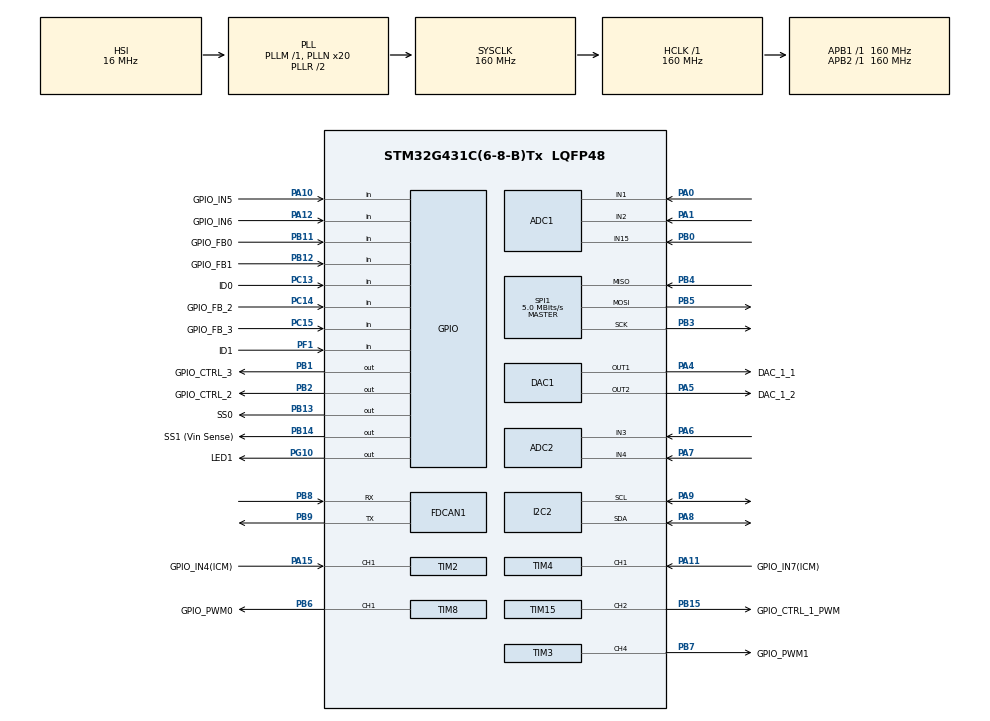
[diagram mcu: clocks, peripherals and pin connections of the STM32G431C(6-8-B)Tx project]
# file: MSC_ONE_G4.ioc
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ADC1.Channel-1\#ChannelRegularConversion=ADC_CHANNEL_1
ADC1.Channel-2\#ChannelRegularConversion=ADC_CHANNEL_2
ADC1.Channel-3\#ChannelRegularConversion=ADC_CHANNEL_15
ADC1.ClockPrescaler=ADC_CLOCK_ASYNC_DIV32
ADC1.ContinuousConvMode=ENABLE
ADC1.DMAContinuousRequests=ENABLE
ADC1.EOCSelection=ADC_EOC_SEQ_CONV
ADC1.NbrOfConversion=3
ADC1.NbrOfConversionFlag=1
ADC1.OffsetNumber-1\#ChannelRegularConversion=ADC_OFFSET_NONE
ADC1.OffsetNumber-2\#ChannelRegularConversion=ADC_OFFSET_NONE
ADC1.OffsetNumber-3\#ChannelRegularConversion=ADC_OFFSET_NONE
ADC1.Rank-1\#ChannelRegularConversion=1
ADC1.Rank-2\#ChannelRegularConversion=2
ADC1.Rank-3\#ChannelRegularConversion=3
ADC1.SamplingTime-1\#ChannelRegularConversion=ADC_SAMPLETIME_92CYCLES_5
ADC1.SamplingTime-2\#ChannelRegularConversion=ADC_SAMPLETIME_92CYCLES_5
ADC1.SamplingTime-3\#ChannelRegularConversion=ADC_SAMPLETIME_92CYCLES_5
ADC1.master=1
ADC2.Channel-0\#ChannelRegularConversion=ADC_CHANNEL_3
ADC2.Channel-1\#ChannelRegularConversion=ADC_CHANNEL_4
ADC2.ClockPrescaler=ADC_CLOCK_ASYNC_DIV32
ADC2.ContinuousConvMode=ENABLE
ADC2.DMAContinuousRequests=ENABLE
ADC2.EOCSelection=ADC_EOC_SEQ_CONV
ADC2.NbrOfConversion=2
ADC2.NbrOfConversionFlag=1
ADC2.OffsetNumber-0\#ChannelRegularConversion=ADC_OFFSET_NONE
ADC2.OffsetNumber-1\#ChannelRegularConversion=ADC_OFFSET_NONE
ADC2.Rank-0\#ChannelRegularConversion=1
ADC2.Rank-1\#ChannelRegularConversion=2
ADC2.SamplingTime-0\#ChannelRegularConversion=ADC_SAMPLETIME_92CYCLES_5
ADC2.SamplingTime-1\#ChannelRegularConversion=ADC_SAMPLETIME_92CYCLES_5
DAC1.DAC_Channel-DAC_OUT2=DAC_CHANNEL_2
Dma.ADC1.1.Direction=DMA_PERIPH_TO_MEMORY
Dma.ADC1.1.EventEnable=DISABLE
Dma.ADC1.1.Instance=DMA1_Channel1
Dma.ADC1.1.MemDataAlignment=DMA_MDATAALIGN_HALFWORD
Dma.ADC1.1.MemInc=DMA_MINC_ENABLE
Dma.ADC1.1.Mode=DMA_CIRCULAR
Dma.ADC1.1.PeriphDataAlignment=DMA_PDATAALIGN_HALFWORD
Dma.ADC1.1.PeriphInc=DMA_PINC_DISABLE
Dma.ADC1.1.Polarity=HAL_DMAMUX_REQ_GEN_RISING
Dma.ADC1.1.Priority=DMA_PRIORITY_MEDIUM
Dma.ADC1.1.RequestNumber=1
Dma.ADC1.1.SignalID=NONE
Dma.ADC1.1.SyncEnable=DISABLE
Dma.ADC1.1.SyncPolarity=HAL_DMAMUX_SYNC_NO_EVENT
Dma.ADC1.1.SyncRequestNumber=1
Dma.ADC1.1.SyncSignalID=NONE
Dma.ADC2.0.Direction=DMA_PERIPH_TO_MEMORY
Dma.ADC2.0.EventEnable=DISABLE
Dma.ADC2.0.Instance=DMA1_Channel2
Dma.ADC2.0.MemDataAlignment=DMA_MDATAALIGN_HALFWORD
Dma.ADC2.0.MemInc=DMA_MINC_ENABLE
Dma.ADC2.0.Mode=DMA_CIRCULAR
Dma.ADC2.0.PeriphDataAlignment=DMA_PDATAALIGN_HALFWORD
Dma.ADC2.0.PeriphInc=DMA_PINC_DISABLE
Dma.ADC2.0.Polarity=HAL_DMAMUX_REQ_GEN_RISING
Dma.ADC2.0.Priority=DMA_PRIORITY_MEDIUM
Dma.ADC2.0.RequestNumber=1
Dma.ADC2.0.SignalID=NONE
Dma.ADC2.0.SyncEnable=DISABLE
Dma.ADC2.0.SyncPolarity=HAL_DMAMUX_SYNC_NO_EVENT
Dma.ADC2.0.SyncRequestNumber=1
Dma.ADC2.0.SyncSignalID=NONE
Dma.Request0=ADC2
Dma.Request1=ADC1
Dma.Request2=TIM4_CH2
Dma.Request3=TIM2_CH2
Dma.Request4=SPI1_RX
Dma.Request5=SPI1_TX
Dma.SPI1_RX.4.Direction=DMA_PERIPH_TO_MEMORY
Dma.SPI1_RX.4.EventEnable=DISABLE
Dma.SPI1_RX.4.Instance=DMA1_Channel5
Dma.SPI1_RX.4.MemDataAlignment=DMA_MDATAALIGN_BYTE
Dma.SPI1_RX.4.MemInc=DMA_MINC_ENABLE
Dma.SPI1_RX.4.Mode=DMA_NORMAL
Dma.SPI1_RX.4.PeriphDataAlignment=DMA_PDATAALIGN_BYTE
Dma.SPI1_RX.4.PeriphInc=DMA_PINC_DISABLE
Dma.SPI1_RX.4.Polarity=HAL_DMAMUX_REQ_GEN_RISING
Dma.SPI1_RX.4.Priority=DMA_PRIORITY_LOW
Dma.SPI1_RX.4.RequestNumber=1
Dma.SPI1_RX.4.SignalID=NONE
Dma.SPI1_RX.4.SyncEnable=DISABLE
Dma.SPI1_RX.4.SyncPolarity=HAL_DMAMUX_SYNC_NO_EVENT
Dma.SPI1_RX.4.SyncRequestNumber=1
Dma.SPI1_RX.4.SyncSignalID=NONE
Dma.SPI1_TX.5.Direction=DMA_MEMORY_TO_PERIPH
Dma.SPI1_TX.5.EventEnable=DISABLE
Dma.SPI1_TX.5.Instance=DMA1_Channel6
Dma.SPI1_TX.5.MemDataAlignment=DMA_MDATAALIGN_BYTE
Dma.SPI1_TX.5.MemInc=DMA_MINC_ENABLE
Dma.SPI1_TX.5.Mode=DMA_NORMAL
Dma.SPI1_TX.5.PeriphDataAlignment=DMA_PDATAALIGN_BYTE
Dma.SPI1_TX.5.PeriphInc=DMA_PINC_DISABLE
Dma.SPI1_TX.5.Polarity=HAL_DMAMUX_REQ_GEN_RISING
Dma.SPI1_TX.5.Priority=DMA_PRIORITY_LOW
Dma.SPI1_TX.5.RequestNumber=1
Dma.SPI1_TX.5.SignalID=NONE
Dma.SPI1_TX.5.SyncEnable=DISABLE
Dma.SPI1_TX.5.SyncPolarity=HAL_DMAMUX_SYNC_NO_EVENT
Dma.SPI1_TX.5.SyncRequestNumber=1
Dma.SPI1_TX.5.SyncSignalID=NONE
Dma.TIM2_CH2.3.Direction=DMA_PERIPH_TO_MEMORY
Dma.TIM2_CH2.3.EventEnable=DISABLE
Dma.TIM2_CH2.3.Instance=DMA1_Channel4
Dma.TIM2_CH2.3.MemDataAlignment=DMA_MDATAALIGN_HALFWORD
Dma.TIM2_CH2.3.MemInc=DMA_MINC_ENABLE
Dma.TIM2_CH2.3.Mode=DMA_CIRCULAR
Dma.TIM2_CH2.3.PeriphDataAlignment=DMA_PDATAALIGN_HALFWORD
Dma.TIM2_CH2.3.PeriphInc=DMA_PINC_DISABLE
Dma.TIM2_CH2.3.Polarity=HAL_DMAMUX_REQ_GEN_RISING
Dma.TIM2_CH2.3.Priority=DMA_PRIORITY_LOW
Dma.TIM2_CH2.3.RequestNumber=1
Dma.TIM2_CH2.3.SignalID=NONE
Dma.TIM2_CH2.3.SyncEnable=DISABLE
Dma.TIM2_CH2.3.SyncPolarity=HAL_DMAMUX_SYNC_NO_EVENT
Dma.TIM2_CH2.3.SyncRequestNumber=1
Dma.TIM2_CH2.3.SyncSignalID=NONE
Dma.TIM4_CH2.2.Direction=DMA_PERIPH_TO_MEMORY
Dma.TIM4_CH2.2.EventEnable=DISABLE
Dma.TIM4_CH2.2.Instance=DMA1_Channel3
Dma.TIM4_CH2.2.MemDataAlignment=DMA_MDATAALIGN_HALFWORD
Dma.TIM4_CH2.2.MemInc=DMA_MINC_ENABLE
Dma.TIM4_CH2.2.Mode=DMA_CIRCULAR
Dma.TIM4_CH2.2.PeriphDataAlignment=DMA_PDATAALIGN_HALFWORD
Dma.TIM4_CH2.2.PeriphInc=DMA_PINC_DISABLE
Dma.TIM4_CH2.2.Polarity=HAL_DMAMUX_REQ_GEN_RISING
Dma.TIM4_CH2.2.Priority=DMA_PRIORITY_LOW
Dma.TIM4_CH2.2.RequestNumber=1
Dma.TIM4_CH2.2.SignalID=NONE
Dma.TIM4_CH2.2.SyncEnable=DISABLE
Dma.TIM4_CH2.2.SyncPolarity=HAL_DMAMUX_SYNC_NO_EVENT
Dma.TIM4_CH2.2.SyncRequestNumber=1
Dma.TIM4_CH2.2.SyncSignalID=NONE
FDCAN1.CalculateBaudRateNominal=500000
FDCAN1.CalculateTimeBitNominal=2000
FDCAN1.CalculateTimeQuantumNominal=125.0
FDCAN1.DataPrescaler=20
FDCAN1.DataSyncJumpWidth=3
FDCAN1.DataTimeSeg1=11
FDCAN1.DataTimeSeg2=4
FDCAN1.NominalPrescaler=20
FDCAN1.NominalSyncJumpWidth=3
FDCAN1.NominalTimeSeg1=11
FDCAN1.NominalTimeSeg2=4
I2C2.Timing=0x30909DEC
Mcu.Family=STM32G4
Mcu.Name=STM32G431C(6-8-B)Tx
Mcu.Package=LQFP48
NVIC.DMA1_Channel1_IRQn=true\:0\:0\:false\:false\:true\:false\:true\:true
NVIC.DMA1_Channel2_IRQn=true\:0\:0\:false\:false\:true\:false\:true\:true
NVIC.DMA1_Channel3_IRQn=true\:0\:0\:false\:false\:true\:false\:true\:true
NVIC.DMA1_Channel4_IRQn=true\:0\:0\:false\:false\:true\:false\:true\:true
NVIC.DMA1_Channel5_IRQn=true\:0\:0\:false\:false\:true\:false\:true\:true
NVIC.DMA1_Channel6_IRQn=true\:0\:0\:false\:false\:true\:false\:true\:true
NVIC.FDCAN1_IT0_IRQn=true\:0\:0\:false\:false\:true\:true\:true\:true
NVIC.I2C2_ER_IRQn=true\:0\:0\:false\:false\:true\:true\:true\:true
NVIC.I2C2_EV_IRQn=true\:0\:0\:false\:false\:true\:true\:true\:true
NVIC.PriorityGroup=NVIC_PRIORITYGROUP_4
NVIC.TIM1_BRK_TIM15_IRQn=true\:0\:0\:false\:false\:true\:true\:true\:true
NVIC.TIM1_UP_TIM16_IRQn=true\:0\:0\:false\:false\:true\:true\:true\:true
NVIC.TIM2_IRQn=true\:0\:0\:false\:false\:true\:true\:true\:true
NVIC.TIM3_IRQn=true\:0\:0\:false\:false\:true\:true\:true\:true
NVIC.TIM4_IRQn=true\:0\:0\:false\:false\:true\:true\:true\:true
NVIC.TIM6_DAC_IRQn=true\:0\:0\:false\:false\:true\:true\:true\:true
NVIC.TIM7_IRQn=true\:0\:0\:true\:false\:true\:true\:true\:true
NVIC.TIM8_UP_IRQn=true\:0\:0\:false\:false\:true\:true\:true\:true
PA0.Mode=IN1-Single-Ended
PA0.Signal=ADC1_IN1
PA1.Mode=IN2-Single-Ended
PA1.Signal=ADC1_IN2
PA10.GPIO_Label=GPIO_IN5
PA10.Signal=GPIO_Input
PA11.GPIO_Label=GPIO_IN7(ICM)
PA11.Signal=S_TIM4_CH1
PA12.GPIO_Label=GPIO_IN6
PA12.Signal=GPIO_Input
PA13.Mode=Serial_Wire
PA13.Signal=SYS_JTMS-SWDIO
PA14.Mode=Serial_Wire
PA14.Signal=SYS_JTCK-SWCLK
PA15.GPIO_Label=GPIO_IN4(ICM)
PA15.Signal=S_TIM2_CH1
PA2.Signal=USART2_TX
PA3.Signal=USART2_RX
PA4.GPIO_Label=DAC_1_1
PA4.Signal=COMP_DAC11_group
PA5.GPIO_Label=DAC_1_2
PA5.Signal=COMP_DAC12_group
PA6.Mode=IN3-Single-Ended
PA6.Signal=ADC2_IN3
PA7.Mode=IN4-Single-Ended
PA7.Signal=ADC2_IN4
PA8.GPIO_Pu=GPIO_PULLUP
PA8.Mode=I2C
PA8.Signal=I2C2_SDA
PA9.GPIO_Pu=GPIO_PULLUP
PA9.Mode=I2C
PA9.Signal=I2C2_SCL
PB0.Mode=IN15-Single-Ended
PB0.Signal=ADC1_IN15
PB1.GPIO_Label=GPIO_CTRL_3
PB1.Signal=GPIO_Output
PB11.GPIO_Label=GPIO_FB0
PB11.Signal=GPIO_Input
PB12.GPIO_Label=GPIO_FB1
PB12.Signal=GPIO_Input
PB13.GPIO_Label=SS0
PB13.GPIO_ModeDefaultOutputPP=GPIO_MODE_OUTPUT_PP
PB13.GPIO_PuPd=GPIO_NOPULL
PB13.GPIO_Speed=GPIO_SPEED_FREQ_HIGH
PB13.PinState=GPIO_PIN_SET
PB13.Signal=GPIO_Output
PB14.GPIO_Label=SS1 (Vin Sense)
PB14.GPIO_ModeDefaultOutputPP=GPIO_MODE_OUTPUT_PP
PB14.GPIO_PuPd=GPIO_NOPULL
PB14.GPIO_Speed=GPIO_SPEED_FREQ_HIGH
PB14.PinState=GPIO_PIN_SET
PB14.Signal=GPIO_Output
PB15.GPIO_Label=GPIO_CTRL_1_PWM
PB15.Signal=S_TIM15_CH2
PB2.GPIO_Label=GPIO_CTRL_2
PB2.Signal=GPIO_Output
PB3.Mode=Full_Duplex_Master
PB3.Signal=SPI1_SCK
PB4.GPIO_PuPd=GPIO_PULLUP
PB4.Mode=Full_Duplex_Master
PB4.Signal=SPI1_MISO
PB5.GPIO_PuPd=GPIO_NOPULL
PB5.Mode=Full_Duplex_Master
PB5.Signal=SPI1_MOSI
PB6.GPIO_Label=GPIO_PWM0\\
PB6.Signal=S_TIM8_CH1
PB7.GPIO_Label=GPIO_PWM1
PB7.Signal=S_TIM3_CH4
PB8-BOOT0.Mode=FDCAN_Activate
PB8-BOOT0.Signal=FDCAN1_RX
PB9.Mode=FDCAN_Activate
PB9.Signal=FDCAN1_TX
PC13.GPIO_Label=ID0
PC13.GPIO_PuPd=GPIO_PULLDOWN
PC13.Signal=GPIO_Input
PC14-OSC32_IN.GPIO_Label=GPIO_FB_2
PC14-OSC32_IN.Signal=GPIO_Input
PC15-OSC32_OUT.GPIO_Label=GPIO_FB_3
PC15-OSC32_OUT.Signal=GPIO_Input
PF0-OSC_IN.Signal=RCC_OSC_IN
PF1-OSC_OUT.GPIO_Label=ID1
PF1-OSC_OUT.GPIO_PuPd=GPIO_PULLDOWN
PF1-OSC_OUT.Signal=GPIO_Input
PG10-NRST.GPIO_Label=LED1
PG10-NRST.GPIO_PuPd=GPIO_NOPULL
PG10-NRST.PinState=GPIO_PIN_RESET
PG10-NRST.Signal=GPIO_Output
ProjectManager.HeapSize=0x200
ProjectManager.StackSize=0x400
ProjectManager.TargetToolchain=Makefile
RCC.ADC12Freq_Value=160000000
RCC.AHBFreq_Value=160000000
RCC.APB1Freq_Value=160000000
RCC.APB1TimFreq_Value=160000000
RCC.APB2Freq_Value=160000000
RCC.APB2TimFreq_Value=160000000
RCC.CK48CLockSelection=RCC_USBCLKSOURCE_HSI48
RCC.CortexFreq_Value=160000000
RCC.EXTERNAL_CLOCK_VALUE=12288000
RCC.HCLKFreq_Value=160000000
RCC.HSE_VALUE=8000000
RCC.HSI48_VALUE=48000000
RCC.HSI_VALUE=16000000
RCC.LSE_VALUE=32768
RCC.PLLN=20
RCC.SYSCLKFreq_VALUE=160000000
RCC.SYSCLKSource=RCC_SYSCLKSOURCE_PLLCLK
RCC.USBFreq_Value=48000000
RCC.VCOOutputFreq_Value=320000000
SH.COMP_DAC11_group.0=DAC1_OUT1,DAC_OUT1
SH.COMP_DAC12_group.0=DAC1_OUT2,DAC_OUT2
SH.S_TIM15_CH2.0=TIM15_CH2,PWM Generation2 CH2
SH.S_TIM2_CH1.0=TIM2_CH1,Input_Capture1_from_TI1
SH.S_TIM2_CH1.1=TIM2_CH1,TriggerSource_TI1FP1
SH.S_TIM3_CH4.0=TIM3_CH4,PWM Generation4 CH4
SH.S_TIM4_CH1.0=TIM4_CH1,TriggerSource_TI1FP1
SH.S_TIM4_CH1.1=TIM4_CH1,Input_Capture1_from_TI1
SH.S_TIM8_CH1.0=TIM8_CH1,PWM Generation1 CH1
SPI1.BaudRatePrescaler=SPI_BAUDRATEPRESCALER_32
SPI1.CLKPhase=SPI_PHASE_2EDGE
SPI1.CLKPolarity=SPI_POLARITY_HIGH
SPI1.CalculateBaudRate=5.0 MBits/s
SPI1.DataSize=SPI_DATASIZE_8BIT
SPI1.Direction=SPI_DIRECTION_2LINES
SPI1.Mode=SPI_MODE_MASTER
SPI1.VirtualType=VM_MASTER
SYS.TrimmingMode=__NULL
SYS.VoltageScaling=SYSCFG_VREFBUF_VOLTAGE_SCALE2
TIM1.PeriodNoDither=100
TIM1.Prescaler=160
TIM15.AutoReloadPreload=TIM_AUTORELOAD_PRELOAD_ENABLE
TIM15.Channel-PWM\ Generation2\ CH2=TIM_CHANNEL_2
TIM15.PeriodNoDither=1000
TIM15.Prescaler=1600
TIM15.PulseNoDither_2=500
TIM2.Channel-Input_Capture1_from_TI1=TIM_CHANNEL_1
TIM2.Channel-Input_Capture2_from_TI1_63=TIM_CHANNEL_2
TIM2.ICFilter_CH1=4
TIM2.Prescaler=1600
TIM3.AutoReloadPreload=TIM_AUTORELOAD_PRELOAD_ENABLE
TIM3.Channel-PWM\ Generation4\ CH4=TIM_CHANNEL_4
TIM3.PeriodNoDither=1000
TIM3.Prescaler=1600
TIM3.PulseNoDither_4=500
TIM4.Channel-Input_Capture1_from_TI1=TIM_CHANNEL_1
TIM4.Channel-Input_Capture2_from_TI1_63=TIM_CHANNEL_2
TIM4.ICFilter_CH1=4
TIM4.Prescaler=1600
TIM7.Prescaler=160
TIM8.AutoReloadPreload=TIM_AUTORELOAD_PRELOAD_ENABLE
TIM8.Channel-PWM\ Generation1\ CH1=TIM_CHANNEL_1
TIM8.PeriodNoDither=1000
TIM8.Prescaler=1600
TIM8.PulseNoDither_1=500
VP_SYS_VS_DBSignals.Mode=DisableDeadBatterySignals
VP_TIM15_VS_ClockSourceINT.Mode=Internal
VP_TIM1_VS_ClockSourceINT.Mode=Internal
VP_TIM2_VS_ControllerModeReset.Mode=Reset Mode
VP_TIM2_VS_indirect_ch1.Mode=Input_Capture2_from_TI1_63
VP_TIM3_VS_ClockSourceINT.Mode=Internal
VP_TIM4_VS_ControllerModeReset.Mode=Reset Mode
VP_TIM4_VS_indirect_ch1.Mode=Input_Capture2_from_TI1_63
VP_TIM7_VS_ClockSourceINT.Mode=Enable_Timer
VP_TIM7_VS_OPM.Mode=OPM_bit
VREF+.Mode=InternalMode
VREF+.Signal=VREFBUF_OUT
board=custom

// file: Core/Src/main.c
/* USER CODE BEGIN Header */
/**
  ******************************************************************************
  * @file           : main.c
  * @brief          : Main program body
  ******************************************************************************
  * @attention
  *
  * Copyright (c) 2023 STMicroelectronics.
  * All rights reserved.
  *
  * This software is licensed under terms that can be found in the LICENSE file
  * in the root directory of this software component.
  * If no LICENSE file comes with this software, it is provided AS-IS.
  *
  ******************************************************************************
  */
/* USER CODE END Header */
#include "main.h"
#include "adc.h"
#include "dac.h"
#include "dma.h"
#include "fdcan.h"
#include "i2c.h"
#include "spi.h"
#include "tim.h"
#include "gpio.h"

void SystemClock_Config(void);
/* USER CODE BEGIN PFP */
extern void device_main_loop();
extern void initDevice();

/* USER CODE END PFP */

int main(void)
{

  /* MCU Configuration--------------------------------------------------------*/

  /* Reset of all peripherals, Initializes the Flash interface and the Systick. */
  HAL_Init();

  /* Configure the system clock */
  SystemClock_Config();

  /* Initialize all configured peripherals */
  MX_GPIO_Init();
  MX_DMA_Init();
  MX_ADC1_Init();
  MX_ADC2_Init();
  MX_DAC1_Init();
  MX_FDCAN1_Init();
  MX_I2C2_Init();
  MX_TIM2_Init();
  MX_TIM3_Init();
  MX_TIM4_Init();
  MX_TIM15_Init();
  MX_TIM1_Init();
  MX_TIM8_Init();
  MX_TIM7_Init();
  MX_SPI1_Init();
  /* USER CODE BEGIN 2 */
    initDevice();

  /* USER CODE END 2 */

  /* Infinite loop */
  /* USER CODE BEGIN WHILE */
  while (1)
  {
    device_main_loop();
    /* USER CODE END WHILE */

  }
}

void SystemClock_Config(void)
{
  RCC_OscInitTypeDef RCC_OscInitStruct = {0};
  RCC_ClkInitTypeDef RCC_ClkInitStruct = {0};

  /** Configure the main internal regulator output voltage
  */
  HAL_PWREx_ControlVoltageScaling(PWR_REGULATOR_VOLTAGE_SCALE1_BOOST);

  /** Initializes the RCC Oscillators according to the specified parameters
  * in the RCC_OscInitTypeDef structure.
  */
  RCC_OscInitStruct.OscillatorType = RCC_OSCILLATORTYPE_HSI;
  RCC_OscInitStruct.HSIState = RCC_HSI_ON;
  RCC_OscInitStruct.HSICalibrationValue = RCC_HSICALIBRATION_DEFAULT;
  RCC_OscInitStruct.PLL.PLLState = RCC_PLL_ON;
  RCC_OscInitStruct.PLL.PLLSource = RCC_PLLSOURCE_HSI;
  RCC_OscInitStruct.PLL.PLLM = RCC_PLLM_DIV1;
  RCC_OscInitStruct.PLL.PLLN = 20;
  RCC_OscInitStruct.PLL.PLLP = RCC_PLLP_DIV2;
  RCC_OscInitStruct.PLL.PLLQ = RCC_PLLQ_DIV2;
  RCC_OscInitStruct.PLL.PLLR = RCC_PLLR_DIV2;
  if (HAL_RCC_OscConfig(&RCC_OscInitStruct) != HAL_OK)
  {
    Error_Handler();
  }

  /** Initializes the CPU, AHB and APB buses clocks
  */
  RCC_ClkInitStruct.ClockType = RCC_CLOCKTYPE_HCLK|RCC_CLOCKTYPE_SYSCLK
                              |RCC_CLOCKTYPE_PCLK1|RCC_CLOCKTYPE_PCLK2;
  RCC_ClkInitStruct.SYSCLKSource = RCC_SYSCLKSOURCE_PLLCLK;
  RCC_ClkInitStruct.AHBCLKDivider = RCC_SYSCLK_DIV1;
  RCC_ClkInitStruct.APB1CLKDivider = RCC_HCLK_DIV1;
  RCC_ClkInitStruct.APB2CLKDivider = RCC_HCLK_DIV1;

  if (HAL_RCC_ClockConfig(&RCC_ClkInitStruct, FLASH_LATENCY_4) != HAL_OK)
  {
    Error_Handler();
  }
}

void Error_Handler(void)
{
  __disable_irq();
  while (1)
  {
  }
}
